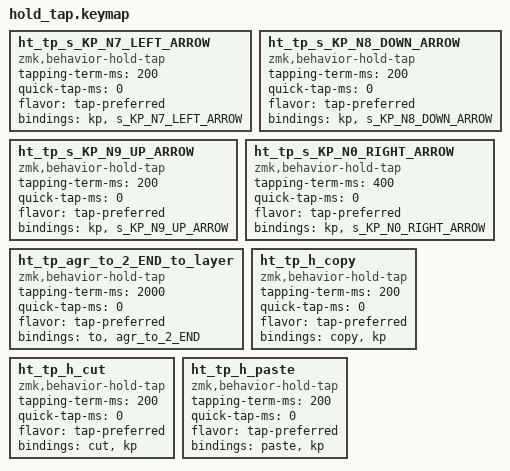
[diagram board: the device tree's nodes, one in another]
/*
    keyoutput[default]  ¦  keyoutput[with modifer]
    ht_tp_x[first char of modifier]_key[default]_key[in combination with modifer](_speciality for hold behavior): x[first char of modifier]_key[default]_key[in combination with modifer](_speciality for hold behavior)
*/

/* 7  ¦  ⬅ */
ht_tp_s_KP_N7_LEFT_ARROW: ht_tp_s_KP_N7_LEFT_ARROW {
    compatible = "zmk,behavior-hold-tap";
    #binding-cells = <2>;
    tapping-term-ms = <200>;
    quick-tap-ms = <0>;
    flavor = "tap-preferred";
    bindings = <&kp>, <&s_KP_N7_LEFT_ARROW>;
};
/* 8  ¦  ⬇ */
ht_tp_s_KP_N8_DOWN_ARROW: ht_tp_s_KP_N8_DOWN_ARROW {
    compatible = "zmk,behavior-hold-tap";
    #binding-cells = <2>;
    tapping-term-ms = <200>;
    quick-tap-ms = <0>;
    flavor = "tap-preferred";
    bindings = <&kp>, <&s_KP_N8_DOWN_ARROW>;
};
/* 9  ¦  ⬆ */
ht_tp_s_KP_N9_UP_ARROW: ht_tp_s_KP_N9_UP_ARROW {
    compatible = "zmk,behavior-hold-tap";
    #binding-cells = <2>;
    tapping-term-ms = <200>;
    quick-tap-ms = <0>;
    flavor = "tap-preferred";
    bindings = <&kp>, <&s_KP_N9_UP_ARROW>;
};
/* 0  ¦  ⮕ */
ht_tp_s_KP_N0_RIGHT_ARROW: ht_tp_s_KP_N0_RIGHT_ARROW {
    compatible = "zmk,behavior-hold-tap";
    #binding-cells = <2>;
    tapping-term-ms = <400>;
    quick-tap-ms = <0>;
    flavor = "tap-preferred";
    bindings = <&kp>, <&s_KP_N0_RIGHT_ARROW>;
};
/* L2  ¦  End */
ht_tp_agr_to_2_END_to_layer: ht_tp_agr_to_2_END_to_layer {
    compatible = "zmk,behavior-hold-tap";
    #binding-cells = <2>;
    tapping-term-ms = <2000>;
    quick-tap-ms = <0>;
    flavor = "tap-preferred";
    bindings = <&to>, <&agr_to_2_END>;
};

//Hold taps with defined hold and undifined taps (_h_ for hold)

/* COPY  */
ht_tp_h_copy: ht_tp_h_copy {
    compatible = "zmk,behavior-hold-tap";
    #binding-cells = <2>;
    tapping-term-ms = <200>;
    quick-tap-ms = <0>;
    flavor = "tap-preferred";
    bindings = <&copy>, <&kp>;
};
/* CUT  */
ht_tp_h_cut: ht_tp_h_cut {
    compatible = "zmk,behavior-hold-tap";
    #binding-cells = <2>;
    tapping-term-ms = <200>;
    quick-tap-ms = <0>;
    flavor = "tap-preferred";
    bindings = <&cut>, <&kp>;
};
/* PASTE  */
ht_tp_h_paste: ht_tp_h_paste {
    compatible = "zmk,behavior-hold-tap";
    #binding-cells = <2>;
    tapping-term-ms = <200>;
    quick-tap-ms = <0>;
    flavor = "tap-preferred";
    bindings = <&paste>, <&kp>;
};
